# HC32F4A0PGTB register map
File version: 1.0
CPU: CM4 r0p1, little endian, MPU, FPU, 4 interrupt priority bits
Registers are 32-bit, read-write, reset 0x0 unless marked. A register's access mark holds for its fields unless they carry their own. Offsets are from the block's base; [hi:lo] are bit positions.

## HASH
Base 0x40008400
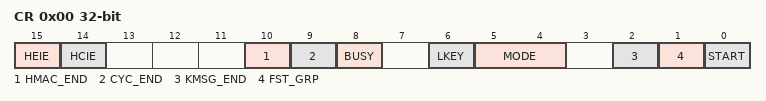
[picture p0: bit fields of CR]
0x00 CR
  [15] HEIE, [14] HCIE, [10] HMAC_END, [9] CYC_END, [8] BUSY, [6] LKEY, [5:4] MODE, [2] KMSG_END, [1] FST_GRP, [0] START
0x10 HR7
0x14 HR6
0x18 HR5
0x1C HR4
0x20 HR3
0x24 HR2
0x28 HR1
0x2C HR0
0x40 DR15
0x44 DR14
0x48 DR13
0x4C DR12
0x50 DR11
0x54 DR10
0x58 DR9
0x5C DR8
0x60 DR7
0x64 DR6
0x68 DR5
0x6C DR4
0x70 DR3
0x74 DR2
0x78 DR1
0x7C DR0

## HRPWM
Base 0x4003C000
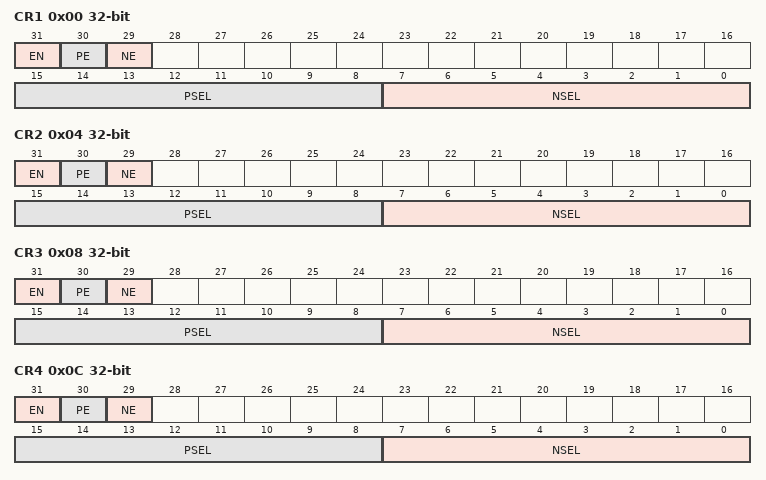
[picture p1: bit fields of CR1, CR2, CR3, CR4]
0x00 CR1
  [31] EN, [30] PE, [29] NE, [15:8] PSEL, [7:0] NSEL
0x04 CR2
  [31] EN, [30] PE, [29] NE, [15:8] PSEL, [7:0] NSEL
0x08 CR3
  [31] EN, [30] PE, [29] NE, [15:8] PSEL, [7:0] NSEL
0x0C CR4
  [31] EN, [30] PE, [29] NE, [15:8] PSEL, [7:0] NSEL
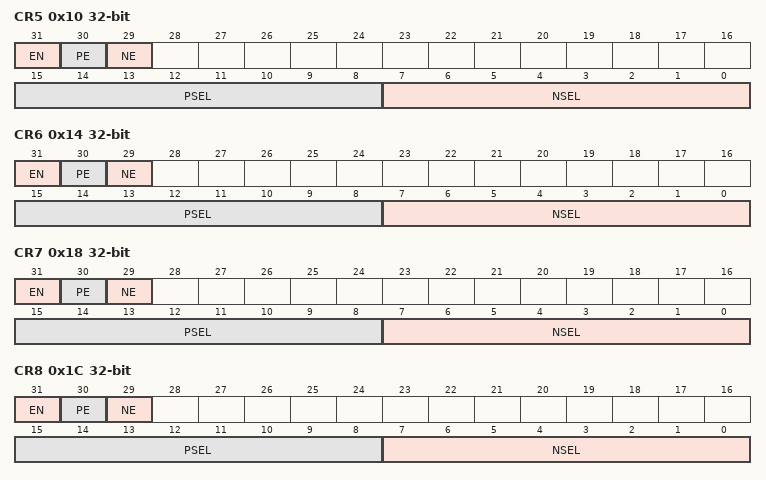
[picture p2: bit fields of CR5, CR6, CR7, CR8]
0x10 CR5
  [31] EN, [30] PE, [29] NE, [15:8] PSEL, [7:0] NSEL
0x14 CR6
  [31] EN, [30] PE, [29] NE, [15:8] PSEL, [7:0] NSEL
0x18 CR7
  [31] EN, [30] PE, [29] NE, [15:8] PSEL, [7:0] NSEL
0x1C CR8
  [31] EN, [30] PE, [29] NE, [15:8] PSEL, [7:0] NSEL
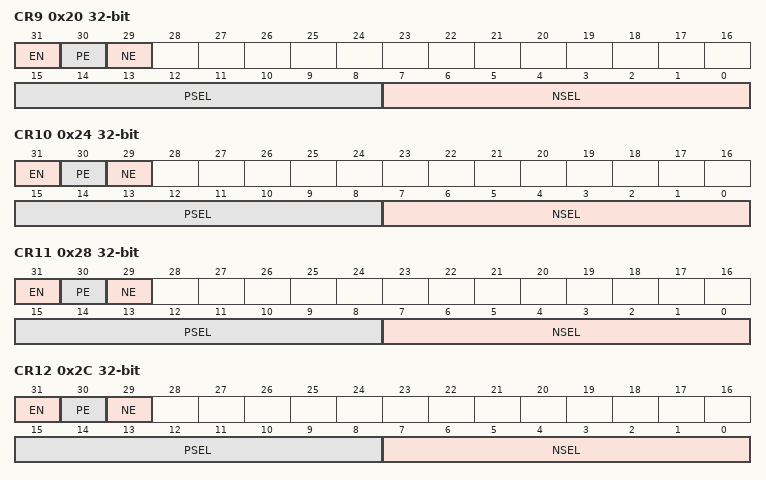
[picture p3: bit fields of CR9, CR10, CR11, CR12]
0x20 CR9
  [31] EN, [30] PE, [29] NE, [15:8] PSEL, [7:0] NSEL
0x24 CR10
  [31] EN, [30] PE, [29] NE, [15:8] PSEL, [7:0] NSEL
0x28 CR11
  [31] EN, [30] PE, [29] NE, [15:8] PSEL, [7:0] NSEL
0x2C CR12
  [31] EN, [30] PE, [29] NE, [15:8] PSEL, [7:0] NSEL
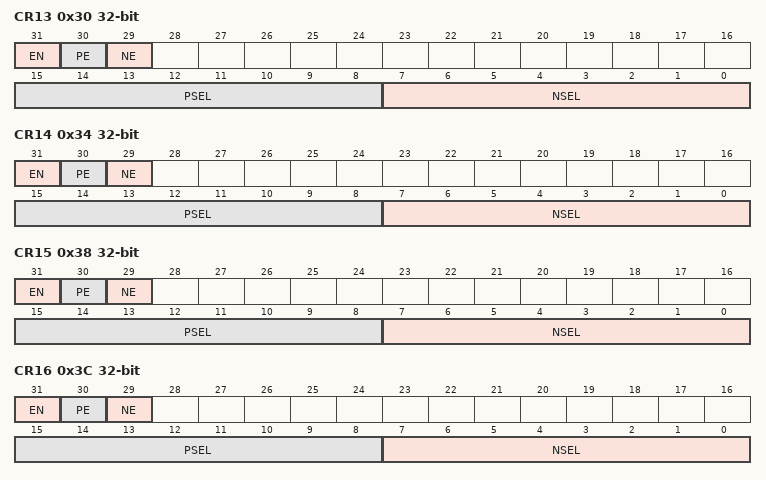
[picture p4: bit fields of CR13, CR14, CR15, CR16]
0x30 CR13
  [31] EN, [30] PE, [29] NE, [15:8] PSEL, [7:0] NSEL
0x34 CR14
  [31] EN, [30] PE, [29] NE, [15:8] PSEL, [7:0] NSEL
0x38 CR15
  [31] EN, [30] PE, [29] NE, [15:8] PSEL, [7:0] NSEL
0x3C CR16
  [31] EN, [30] PE, [29] NE, [15:8] PSEL, [7:0] NSEL
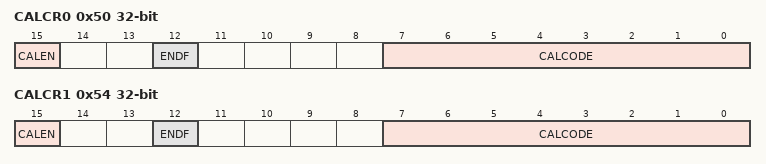
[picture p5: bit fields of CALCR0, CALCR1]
0x50 CALCR0
  [15] CALEN, [12] ENDF, [7:0] CALCODE
0x54 CALCR1
  [15] CALEN, [12] ENDF, [7:0] CALCODE

## I2C1 — desc I2C
Base 0x4004E000
Same registers: I2C2 0x4004E400, I2C3 0x4004E800, I2C4 0x4004EC00, I2C5 0x4004F000, I2C6 0x4004F400
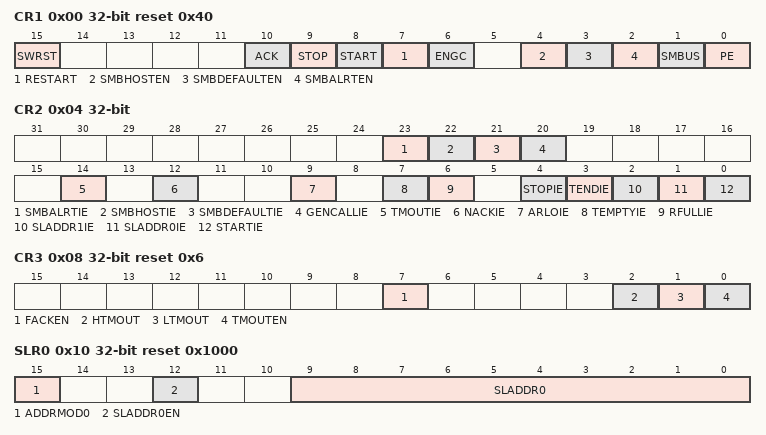
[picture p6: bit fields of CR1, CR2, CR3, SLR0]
0x00 CR1 reset 0x40
  [15] SWRST, [10] ACK, [9] STOP, [8] START, [7] RESTART, [6] ENGC, [4] SMBHOSTEN, [3] SMBDEFAULTEN, [2] SMBALRTEN, [1] SMBUS, [0] PE
0x04 CR2
  [23] SMBALRTIE, [22] SMBHOSTIE, [21] SMBDEFAULTIE, [20] GENCALLIE, [14] TMOUTIE, [12] NACKIE, [9] ARLOIE, [7] TEMPTYIE, [6] RFULLIE, [4] STOPIE, [3] TENDIE, [2] SLADDR1IE, [1] SLADDR0IE, [0] STARTIE
0x08 CR3 reset 0x6
  [7] FACKEN, [2] HTMOUT, [1] LTMOUT, [0] TMOUTEN
0x0C CR4 reset 0x300307
  [10] BUSWAIT
0x10 SLR0 reset 0x1000
  [15] ADDRMOD0, [12] SLADDR0EN, [9:0] SLADDR0
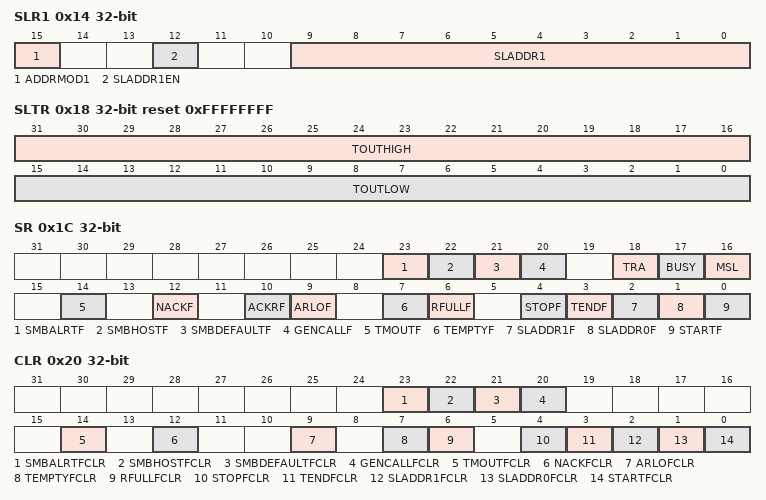
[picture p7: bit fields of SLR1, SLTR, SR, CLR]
0x14 SLR1
  [15] ADDRMOD1, [12] SLADDR1EN, [9:0] SLADDR1
0x18 SLTR reset 0xFFFFFFFF
  [31:16] TOUTHIGH, [15:0] TOUTLOW
0x1C SR
  [23] SMBALRTF, [22] SMBHOSTF, [21] SMBDEFAULTF, [20] GENCALLF, [18] TRA, [17] BUSY, [16] MSL, [14] TMOUTF, [12] NACKF, [10] ACKRF, [9] ARLOF, [7] TEMPTYF, [6] RFULLF, [4] STOPF, [3] TENDF, [2] SLADDR1F, [1] SLADDR0F, [0] STARTF
0x20 CLR wo
  [23] SMBALRTFCLR, [22] SMBHOSTFCLR, [21] SMBDEFAULTFCLR, [20] GENCALLFCLR, [14] TMOUTFCLR, [12] NACKFCLR, [9] ARLOFCLR, [7] TEMPTYFCLR, [6] RFULLFCLR, [4] STOPFCLR, [3] TENDFCLR, [2] SLADDR1FCLR, [1] SLADDR0FCLR, [0] STARTFCLR
0x24 DTR 8-bit wo reset 0xFF
  [7:0] DT
0x28 DRR 8-bit ro
  [7:0] DR
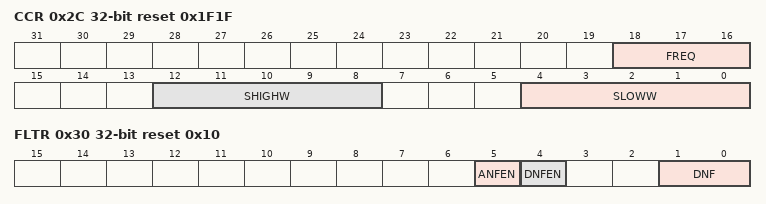
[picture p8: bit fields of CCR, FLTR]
0x2C CCR reset 0x1F1F
  [18:16] FREQ, [12:8] SHIGHW, [4:0] SLOWW
0x30 FLTR reset 0x10
  [5] ANFEN, [4] DNFEN, [1:0] DNF

## I2S1 — desc I2S
Base 0x4001E000
Same registers: I2S2 0x4001E400, I2S3 0x40022000, I2S4 0x40022400
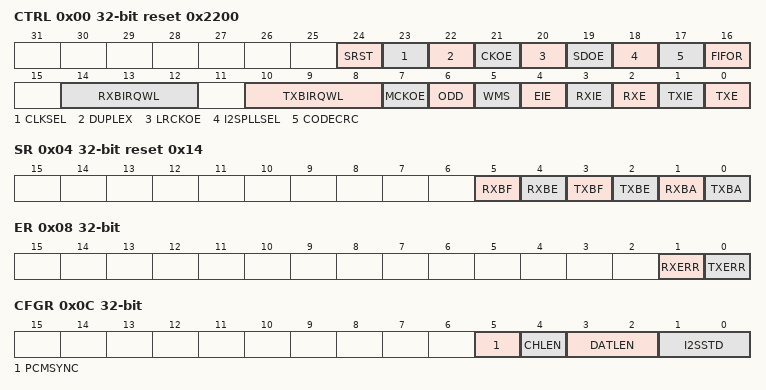
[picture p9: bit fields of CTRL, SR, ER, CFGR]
0x00 CTRL reset 0x2200
  [24] SRST, [23] CLKSEL, [22] DUPLEX, [21] CKOE, [20] LRCKOE, [19] SDOE, [18] I2SPLLSEL, [17] CODECRC, [16] FIFOR, [14:12] RXBIRQWL, [10:8] TXBIRQWL, [7] MCKOE, [6] ODD, [5] WMS, [4] EIE, [3] RXIE, [2] RXE, [1] TXIE, [0] TXE
0x04 SR ro reset 0x14
  [5] RXBF, [4] RXBE, [3] TXBF, [2] TXBE, [1] RXBA, [0] TXBA
0x08 ER
  [1] RXERR, [0] TXERR
0x0C CFGR
  [5] PCMSYNC, [4] CHLEN, [3:2] DATLEN, [1:0] I2SSTD
0x10 TXBUF wo
0x14 RXBUF ro
0x18 PR reset 0x2
  [7:0] I2SDIV

## ICG
Base 0x00000400
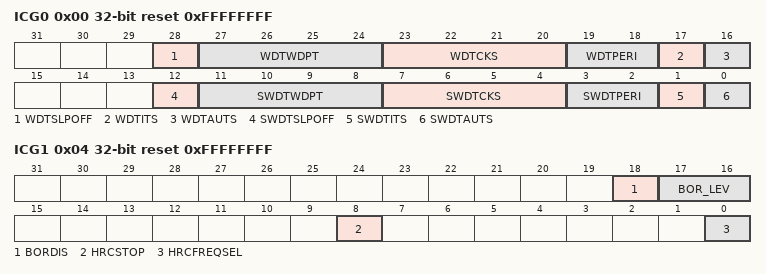
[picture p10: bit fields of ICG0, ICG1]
0x00 ICG0 ro reset 0xFFFFFFFF
  [28] WDTSLPOFF, [27:24] WDTWDPT, [23:20] WDTCKS, [19:18] WDTPERI, [17] WDTITS, [16] WDTAUTS, [12] SWDTSLPOFF, [11:8] SWDTWDPT, [7:4] SWDTCKS, [3:2] SWDTPERI, [1] SWDTITS, [0] SWDTAUTS
0x04 ICG1 ro reset 0xFFFFFFFF
  [18] BORDIS, [17:16] BOR_LEV, [8] HRCSTOP, [0] HRCFREQSEL
0x0C ICG3 ro reset 0xFFFFFFFF
  [15:0] DBUSPRT
